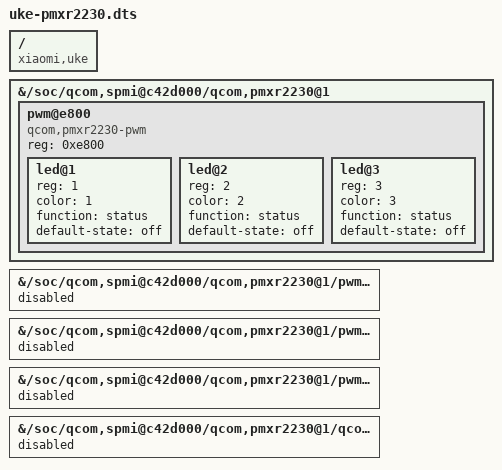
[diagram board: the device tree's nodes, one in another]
// SPDX-License-Identifier: GPL-2.0-only
/dts-v1/;
/plugin/;

/ {
	compatible = "xiaomi,uke";

	fragment@0 {
		target-path = "/soc/qcom,spmi@c42d000/qcom,pmxr2230@1";
		__overlay__ {
			#address-cells = <1>;
			#size-cells = <0>;

			pwm@e800 {
				compatible = "qcom,pmxr2230-pwm";
				reg = <0xe800>;
				#address-cells = <1>;
				#size-cells = <0>;
				#pwm-cells = <2>;
				status = "okay";

				led@1 {
					reg = <1>;
					color = <1>; /* LED_COLOR_ID_RED */
					function = "status";
					default-state = "off";
				};

				led@2 {
					reg = <2>;
					color = <2>; /* LED_COLOR_ID_GREEN */
					function = "status";
					default-state = "off";
				};

				led@3 {
					reg = <3>;
					color = <3>; /* LED_COLOR_ID_BLUE */
					function = "status";
					default-state = "off";
				};
			};
		};
	};

	fragment@1 {
		target-path = "/soc/qcom,spmi@c42d000/qcom,pmxr2230@1/pwms@e800";
		__overlay__ { status = "disabled"; };
	};

	fragment@2 {
		target-path = "/soc/qcom,spmi@c42d000/qcom,pmxr2230@1/pwms@e900";
		__overlay__ { status = "disabled"; };
	};

	fragment@3 {
		target-path = "/soc/qcom,spmi@c42d000/qcom,pmxr2230@1/pwms@eb00";
		__overlay__ { status = "disabled"; };
	};

	fragment@4 {
		target-path = "/soc/qcom,spmi@c42d000/qcom,pmxr2230@1/qcom,leds@ef00";
		__overlay__ { status = "disabled"; };
	};
};
